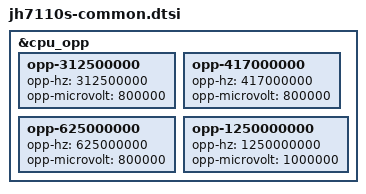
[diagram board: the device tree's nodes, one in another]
// SPDX-License-Identifier: GPL-2.0 OR MIT
/*
 * Copyright (C) 2025 StarFive Technology Co., Ltd.
 * Copyright (C) 2025 Hal Feng <hal.feng@starfivetech.com>
 */

/dts-v1/;
#include "jh711x-common.dtsi"

&cpu_opp {
	opp-312500000 {
		opp-hz = /bits/ 64 <312500000>;
		opp-microvolt = <800000>;
	};
	opp-417000000 {
		opp-hz = /bits/ 64 <417000000>;
		opp-microvolt = <800000>;
	};
	opp-625000000 {
		opp-hz = /bits/ 64 <625000000>;
		opp-microvolt = <800000>;
	};
	opp-1250000000 {
		opp-hz = /bits/ 64 <1250000000>;
		opp-microvolt = <1000000>;
	};
};
